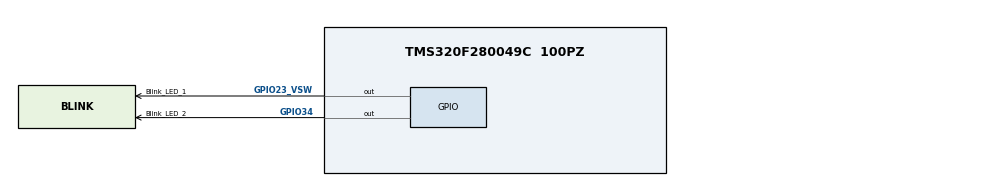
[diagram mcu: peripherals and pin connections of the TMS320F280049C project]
/**
 * These arguments were used when this file was generated. They will be automatically applied on subsequent loads
 * via the GUI or CLI. Run CLI with '--help' for additional information on how to override these arguments.
 * @cliArgs --device "F28004x" --part "F28004x_100PZ" --package "F28004x_100PZ" --product "C2000WARE@4.01.00.00"
 * @v2CliArgs --device "TMS320F280049C" --package "100PZ" --product "C2000WARE@4.01.00.00"
 * @versions {"tool":"1.22.0+3893"}
 */

/**
 * Import the modules used in this configuration.
 */
const cputimer  = scripting.addModule("/driverlib/cputimer.js", {}, false);
const cputimer1 = cputimer.addInstance();
const gpio      = scripting.addModule("/driverlib/gpio.js", {}, false);
const gpio1     = gpio.addInstance();
const gpio2     = gpio.addInstance();

/**
 * Write custom configuration values to the imported modules.
 */
cputimer1.$name                    = "Led_Toggle_Timer";
cputimer1.enableInterrupt          = true;
cputimer1.registerInterrupts       = true;
cputimer1.startTimer               = true;
cputimer1.timerPeriod              = 100000000;
cputimer1.timerInt.enableInterrupt = true;

gpio1.$name             = "Blink_LED_1";
gpio1.direction         = "GPIO_DIR_MODE_OUT";
gpio1.writeInitialValue = true;
gpio1.gpioPin.$assign   = "GPIO23_VSW";

gpio2.$name             = "Blink_LED_2";
gpio2.direction         = "GPIO_DIR_MODE_OUT";
gpio2.writeInitialValue = true;
gpio2.gpioPin.$assign   = "GPIO34";
